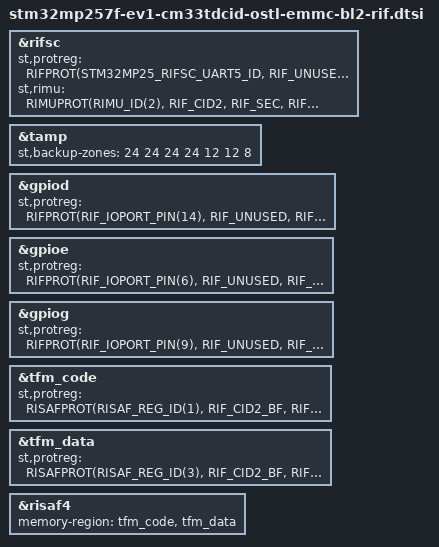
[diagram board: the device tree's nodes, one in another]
// SPDX-License-Identifier: (GPL-2.0-only OR BSD-3-Clause)
/*
 * Copyright (C) STMicroelectronics 2022 - All Rights Reserved
 */

/*
 * stm32mp257f device tree configuration
 * Project : ostl
 * Generated by XLmx tool version 2.7 - 12/2/2024 11:25:43 AM
 */

&rifsc {
	st,protreg = <
		RIFPROT(STM32MP25_RIFSC_UART5_ID, RIF_UNUSED, RIF_UNLOCK, RIF_SEC, RIF_PRIV, RIF_CID2, RIF_SEM_DIS, RIF_CFEN)
		RIFPROT(STM32MP25_RIFSC_I2C7_ID, RIF_UNUSED, RIF_UNLOCK, RIF_SEC, RIF_PRIV, RIF_CID2, RIF_SEM_DIS, RIF_CFEN)
		RIFPROT(STM32MP25_RIFSC_SDMMC2_ID, RIF_UNUSED, RIF_UNLOCK, RIF_SEC, RIF_PRIV, RIF_CID2, RIF_SEM_DIS, RIF_CFEN)
		RIFPROT(STM32MP25_RIFSC_RNG_ID, RIF_UNUSED, RIF_UNLOCK, RIF_SEC, RIF_PRIV, RIF_CID2, RIF_SEM_DIS, RIF_CFEN)
	>;
};

&tamp {
	st,backup-zones = <24 24 24 24 12 12 8>;
};

&gpiod {
	st,protreg = <
		RIFPROT(RIF_IOPORT_PIN(14), RIF_UNUSED, RIF_UNLOCK, RIF_SEC, RIF_PRIV, RIF_CID2, RIF_SEM_DIS, RIF_CFEN)
		RIFPROT(RIF_IOPORT_PIN(15), RIF_UNUSED, RIF_UNLOCK, RIF_SEC, RIF_PRIV, RIF_CID2, RIF_SEM_DIS, RIF_CFEN)
	>;
};

&gpioe {
	st,protreg = <
		RIFPROT(RIF_IOPORT_PIN(6), RIF_UNUSED, RIF_UNLOCK, RIF_SEC, RIF_PRIV, RIF_CID2, RIF_SEM_DIS, RIF_CFEN)
		RIFPROT(RIF_IOPORT_PIN(7), RIF_UNUSED, RIF_UNLOCK, RIF_SEC, RIF_PRIV, RIF_CID2, RIF_SEM_DIS, RIF_CFEN)
		RIFPROT(RIF_IOPORT_PIN(8), RIF_UNUSED, RIF_UNLOCK, RIF_SEC, RIF_PRIV, RIF_CID2, RIF_SEM_DIS, RIF_CFEN)
		RIFPROT(RIF_IOPORT_PIN(9), RIF_UNUSED, RIF_UNLOCK, RIF_SEC, RIF_PRIV, RIF_CID2, RIF_SEM_DIS, RIF_CFEN)
		RIFPROT(RIF_IOPORT_PIN(10), RIF_UNUSED, RIF_UNLOCK, RIF_SEC, RIF_PRIV, RIF_CID2, RIF_SEM_DIS, RIF_CFEN)
		RIFPROT(RIF_IOPORT_PIN(11), RIF_UNUSED, RIF_UNLOCK, RIF_SEC, RIF_PRIV, RIF_CID2, RIF_SEM_DIS, RIF_CFEN)
		RIFPROT(RIF_IOPORT_PIN(12), RIF_UNUSED, RIF_UNLOCK, RIF_SEC, RIF_PRIV, RIF_CID2, RIF_SEM_DIS, RIF_CFEN)
		RIFPROT(RIF_IOPORT_PIN(13), RIF_UNUSED, RIF_UNLOCK, RIF_SEC, RIF_PRIV, RIF_CID2, RIF_SEM_DIS, RIF_CFEN)
		RIFPROT(RIF_IOPORT_PIN(14), RIF_UNUSED, RIF_UNLOCK, RIF_SEC, RIF_PRIV, RIF_CID2, RIF_SEM_DIS, RIF_CFEN)
		RIFPROT(RIF_IOPORT_PIN(15), RIF_UNUSED, RIF_UNLOCK, RIF_SEC, RIF_PRIV, RIF_CID2, RIF_SEM_DIS, RIF_CFEN)
	>;
};

&gpiog {
	st,protreg = <
		RIFPROT(RIF_IOPORT_PIN(9), RIF_UNUSED, RIF_UNLOCK, RIF_SEC, RIF_PRIV, RIF_CID2, RIF_SEM_DIS, RIF_CFEN)
		RIFPROT(RIF_IOPORT_PIN(10), RIF_UNUSED, RIF_UNLOCK, RIF_SEC, RIF_PRIV, RIF_CID2, RIF_SEM_DIS, RIF_CFEN)
	>;
};

&rifsc {
	st,rimu = <
		RIMUPROT(RIMU_ID(2), RIF_CID2, RIF_SEC, RIF_PRIV, RIF_CIDSEL_M)
	>;
};

&tfm_code {
	st,protreg = <RISAFPROT(RISAF_REG_ID(1), RIF_CID2_BF, RIF_CID2_BF, RIF_UNUSED, RIF_SEC, RIF_ENC_EN, RIF_BREN_EN)>;
};

&tfm_data {
	st,protreg = <RISAFPROT(RISAF_REG_ID(3), RIF_CID2_BF, RIF_CID2_BF, RIF_UNUSED, RIF_SEC, RIF_ENC_EN, RIF_BREN_EN)>;
};

&risaf4 {
	memory-region = <&tfm_code>, <&tfm_data>;
};
